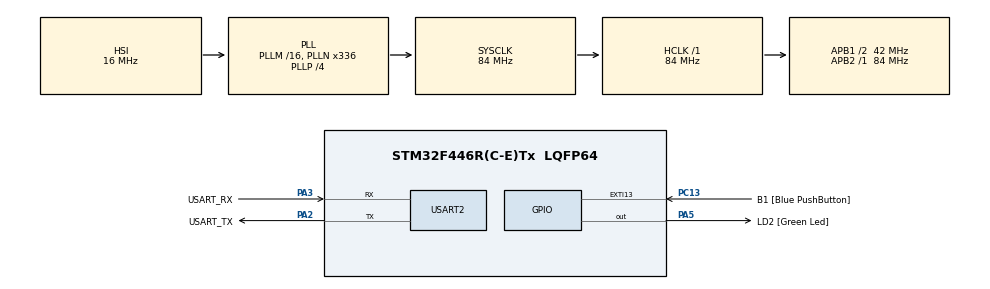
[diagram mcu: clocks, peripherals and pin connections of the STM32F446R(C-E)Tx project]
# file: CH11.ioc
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Mcu.Family=STM32F4
Mcu.Name=STM32F446R(C-E)Tx
Mcu.Package=LQFP64
NVIC.PriorityGroup=NVIC_PRIORITYGROUP_0
PA13.GPIO_Label=TMS
PA13.Mode=Serial_Wire
PA13.Signal=SYS_JTMS-SWDIO
PA14.GPIO_Label=TCK
PA14.Mode=Serial_Wire
PA14.Signal=SYS_JTCK-SWCLK
PA2.GPIO_Label=USART_TX
PA2.Mode=Asynchronous
PA2.Signal=USART2_TX
PA3.GPIO_Label=USART_RX
PA3.Mode=Asynchronous
PA3.Signal=USART2_RX
PA5.GPIO_Label=LD2 [Green Led]
PA5.Signal=GPIO_Output
PB3.GPIO_Label=SWO
PB3.Signal=SYS_JTDO-SWO
PC13.GPIO_Label=B1 [Blue PushButton]
PC13.GPIO_ModeDefaultEXTI=GPIO_MODE_IT_FALLING
PC13.Signal=GPXTI13
PC14-OSC32_IN.Mode=LSE-External-Oscillator
PC14-OSC32_IN.Signal=RCC_OSC32_IN
PC15-OSC32_OUT.Mode=LSE-External-Oscillator
PC15-OSC32_OUT.Signal=RCC_OSC32_OUT
PH0-OSC_IN.Mode=HSE-External-Oscillator
PH0-OSC_IN.Signal=RCC_OSC_IN
PH1-OSC_OUT.Mode=HSE-External-Oscillator
PH1-OSC_OUT.Signal=RCC_OSC_OUT
ProjectManager.HeapSize=0x200
ProjectManager.StackSize=0x400
ProjectManager.TargetToolchain=STM32CubeIDE
RCC.48MHZClocksFreq_Value=84000000
RCC.AHBFreq_Value=84000000
RCC.APB1CLKDivider=RCC_HCLK_DIV2
RCC.APB1Freq_Value=42000000
RCC.APB1TimFreq_Value=84000000
RCC.APB2Freq_Value=84000000
RCC.APB2TimFreq_Value=84000000
RCC.CortexFreq_Value=84000000
RCC.FLatency-AdvancedSettings=FLASH_LATENCY_2
RCC.HCLKFreq_Value=84000000
RCC.HSE_VALUE=8000000
RCC.HSI_VALUE=16000000
RCC.PLLN=336
RCC.PLLP=RCC_PLLP_DIV4
RCC.SYSCLKFreq_VALUE=84000000
RCC.SYSCLKSource=RCC_SYSCLKSOURCE_PLLCLK
RCC.USBFreq_Value=168000000
RCC.VCOOutputFreq_Value=336000000
USART2.VirtualMode=VM_ASYNC
board=NUCLEO-F446RE

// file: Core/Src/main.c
/* USER CODE BEGIN Header */
/**
  ******************************************************************************
  * @file           : main.c
  * @brief          : Main program body
  ******************************************************************************
  * @attention
  *
  * <h2><center>&copy; Copyright (c) 2021 STMicroelectronics.
  * All rights reserved.</center></h2>
  *
  * This software component is licensed by ST under BSD 3-Clause license,
  * the "License"; You may not use this file except in compliance with the
  * License. You may obtain a copy of the License at:
  *                        opensource.org/licenses/BSD-3-Clause
  *
  ******************************************************************************
  */
/* USER CODE END Header */
// 学习：引入本工程板级引脚别名和错误处理声明。
#include "main.h"

// 学习：保存外设运行状态、配置和回调关联，初始化后供后续 HAL 操作复用。
UART_HandleTypeDef huart2;

// 学习：建立本章 PLL 与总线分频；频率必须以本函数参数推导，不能跨章节照搬（此处为声明）。
void SystemClock_Config(void);
// 学习：使能端口时钟并配置板载按键/LED；复用引脚由对应外设初始化接管（此处为声明）。
static void MX_GPIO_Init(void);
// 学习：设置 USART2 为 115200、8N1，用于 ST-LINK 虚拟串口观察（此处为声明）。
static void MX_USART2_UART_Init(void);

// 学习：本子例入口：先建立 HAL/时钟/外设，再进入本文件给定的业务流程。
int main(void)
{

  /* MCU Configuration--------------------------------------------------------*/

  /* Reset of all peripherals, Initializes the Flash interface and the Systick. */
  // 学习：复位 HAL 状态、初始化 Flash 与毫秒时基，并进入 HAL_MspInit 板级回调。
  HAL_Init();

  /* Configure the system clock */
  // 学习：建立本章 PLL 与总线分频；频率必须以本函数参数推导，不能跨章节照搬。
  SystemClock_Config();

  /* Initialize all configured peripherals */
  // 学习：使能端口时钟并配置板载按键/LED；复用引脚由对应外设初始化接管。
  MX_GPIO_Init();
  // 学习：设置 USART2 为 115200、8N1，用于 ST-LINK 虚拟串口观察。
  MX_USART2_UART_Init();

  /* Infinite loop */
  /* USER CODE BEGIN WHILE */
  // 学习：进入持续业务或空转等待；是否更新输出取决于循环体。
  while (1)
  {
    /* USER CODE END WHILE */

  }
}

// 学习：建立本章 PLL 与总线分频；频率必须以本函数参数推导，不能跨章节照搬。
void SystemClock_Config(void)
{
  // 学习：为本次硬件初始化准备配置结构，随后逐字段设置有效参数。
  RCC_OscInitTypeDef RCC_OscInitStruct = {0};
  // 学习：为本次硬件初始化准备配置结构，随后逐字段设置有效参数。
  RCC_ClkInitTypeDef RCC_ClkInitStruct = {0};

  /** Configure the main internal regulator output voltage
  */
  // 学习：开启 PWR 外设或端口时钟，使寄存器访问与外设初始化具备时钟前提。
  __HAL_RCC_PWR_CLK_ENABLE();
  // 学习：设置内部调压器电压等级以满足当前系统时钟要求。
  __HAL_PWR_VOLTAGESCALING_CONFIG(PWR_REGULATOR_VOLTAGE_SCALE3);
  /** Initializes the RCC Oscillators according to the specified parameters
  * in the RCC_OscInitTypeDef structure.
  */
  // 学习：选择本次配置涉及的振荡源集合。
  RCC_OscInitStruct.OscillatorType = RCC_OSCILLATORTYPE_HSI;
  // 学习：请求内部高速 RC 状态。
  RCC_OscInitStruct.HSIState = RCC_HSI_ON;
  // 学习：设置 HSI 校准修调码。
  RCC_OscInitStruct.HSICalibrationValue = RCC_HSICALIBRATION_DEFAULT;
  // 学习：选择 PLL 状态。
  RCC_OscInitStruct.PLL.PLLState = RCC_PLL_ON;
  // 学习：选择 PLL 输入振荡源。
  RCC_OscInitStruct.PLL.PLLSource = RCC_PLLSOURCE_HSI;
  // 学习：设置 PLL 输入分频系数。
  RCC_OscInitStruct.PLL.PLLM = 16;
  // 学习：设置 PLL VCO 倍频系数。
  RCC_OscInitStruct.PLL.PLLN = 336;
  // 学习：设置主系统 PLL 输出分频。
  RCC_OscInitStruct.PLL.PLLP = RCC_PLLP_DIV4;
  // 学习：设置 PLL Q 输出分频。
  RCC_OscInitStruct.PLL.PLLQ = 2;
  // 学习：设置 PLL R 输出分频。
  RCC_OscInitStruct.PLL.PLLR = 2;
  // 学习：按结构体启用 HSI/LSE/PLL，建立系统所需振荡源。
  if (HAL_RCC_OscConfig(&RCC_OscInitStruct) != HAL_OK)
  {
    // 学习：错误分支入口；原例若关闭中断并死循环，则只能调试定位或复位恢复。
    Error_Handler();
  }
  /** Initializes the CPU, AHB and APB buses clocks
  */
  // 学习：选择本次要配置的总线时钟域。
  RCC_ClkInitStruct.ClockType = RCC_CLOCKTYPE_HCLK|RCC_CLOCKTYPE_SYSCLK
                              |RCC_CLOCKTYPE_PCLK1|RCC_CLOCKTYPE_PCLK2;
  // 学习：选择系统时钟来源。
  RCC_ClkInitStruct.SYSCLKSource = RCC_SYSCLKSOURCE_PLLCLK;
  // 学习：设置 HCLK 相对 SYSCLK 的分频。
  RCC_ClkInitStruct.AHBCLKDivider = RCC_SYSCLK_DIV1;
  // 学习：设置低速 APB 总线分频；定时器可能采用倍频时钟。
  RCC_ClkInitStruct.APB1CLKDivider = RCC_HCLK_DIV2;
  // 学习：设置高速 APB 总线分频。
  RCC_ClkInitStruct.APB2CLKDivider = RCC_HCLK_DIV1;

  // 学习：选择系统时钟并设置 AHB/APB 分频及 Flash 等待周期。
  if (HAL_RCC_ClockConfig(&RCC_ClkInitStruct, FLASH_LATENCY_2) != HAL_OK)
  {
    // 学习：错误分支入口；原例若关闭中断并死循环，则只能调试定位或复位恢复。
    Error_Handler();
  }
}

// 学习：设置 USART2 为 115200、8N1，用于 ST-LINK 虚拟串口观察。
static void MX_USART2_UART_Init(void)
{

  // 学习：选择实际硬件外设或 DMA Stream，而非新建一个外设。
  huart2.Instance = USART2;
  // 学习：设置串口速率，单位 bit/s。
  huart2.Init.BaudRate = 115200;
  // 学习：设置串口每帧数据位数。
  huart2.Init.WordLength = UART_WORDLENGTH_8B;
  // 学习：设置串口停止位数。
  huart2.Init.StopBits = UART_STOPBITS_1;
  // 学习：设置串口奇偶校验方式。
  huart2.Init.Parity = UART_PARITY_NONE;
  // 学习：选择 GPIO/DMA/UART 对应的工作模式。
  huart2.Init.Mode = UART_MODE_TX_RX;
  // 学习：选择串口硬件流控方式。
  huart2.Init.HwFlowCtl = UART_HWCONTROL_NONE;
  // 学习：设置串口过采样倍数。
  huart2.Init.OverSampling = UART_OVERSAMPLING_16;
  // 学习：按句柄中的波特率和帧格式配置 USART2，并请求 MSP 配置引脚和时钟。
  if (HAL_UART_Init(&huart2) != HAL_OK)
  {
    // 学习：错误分支入口；原例若关闭中断并死循环，则只能调试定位或复位恢复。
    Error_Handler();
  }

}

// 学习：使能端口时钟并配置板载按键/LED；复用引脚由对应外设初始化接管。
static void MX_GPIO_Init(void)
{
  // 学习：为本次硬件初始化准备配置结构，随后逐字段设置有效参数。
  GPIO_InitTypeDef GPIO_InitStruct = {0};

  /* GPIO Ports Clock Enable */
  // 学习：开启 GPIOC 外设或端口时钟，使寄存器访问与外设初始化具备时钟前提。
  __HAL_RCC_GPIOC_CLK_ENABLE();
  // 学习：开启 GPIOH 外设或端口时钟，使寄存器访问与外设初始化具备时钟前提。
  __HAL_RCC_GPIOH_CLK_ENABLE();
  // 学习：开启 GPIOA 外设或端口时钟，使寄存器访问与外设初始化具备时钟前提。
  __HAL_RCC_GPIOA_CLK_ENABLE();
  // 学习：开启 GPIOB 外设或端口时钟，使寄存器访问与外设初始化具备时钟前提。
  __HAL_RCC_GPIOB_CLK_ENABLE();

  /*Configure GPIO pin Output Level */
  // 学习：将 LD2 等输出引脚设为指定初始电平。
  HAL_GPIO_WritePin(LD2_GPIO_Port, LD2_Pin, GPIO_PIN_RESET);

  /*Configure GPIO pin : B1_Pin */
  // 学习：指定本次配置的一个或多个引脚位掩码。
  GPIO_InitStruct.Pin = B1_Pin;
  // 学习：选择 GPIO/DMA/UART 对应的工作模式。
  GPIO_InitStruct.Mode = GPIO_MODE_IT_FALLING;
  // 学习：设置内部上拉/下拉/无拉电阻。
  GPIO_InitStruct.Pull = GPIO_NOPULL;
  // 学习：按 Pin/Mode/Pull/Speed/Alternate 将端口引脚配置为业务所需模式。
  HAL_GPIO_Init(B1_GPIO_Port, &GPIO_InitStruct);

  /*Configure GPIO pin : LD2_Pin */
  // 学习：指定本次配置的一个或多个引脚位掩码。
  GPIO_InitStruct.Pin = LD2_Pin;
  // 学习：选择 GPIO/DMA/UART 对应的工作模式。
  GPIO_InitStruct.Mode = GPIO_MODE_OUTPUT_PP;
  // 学习：设置内部上拉/下拉/无拉电阻。
  GPIO_InitStruct.Pull = GPIO_NOPULL;
  // 学习：设置 GPIO 输出沿驱动速度等级。
  GPIO_InitStruct.Speed = GPIO_SPEED_FREQ_LOW;
  // 学习：按 Pin/Mode/Pull/Speed/Alternate 将端口引脚配置为业务所需模式。
  HAL_GPIO_Init(LD2_GPIO_Port, &GPIO_InitStruct);

}

// 学习：错误分支入口；原例若关闭中断并死循环，则只能调试定位或复位恢复。
void Error_Handler(void)
{
  /* USER CODE BEGIN Error_Handler_Debug */
  /* User can add his own implementation to report the HAL error return state */
  // 学习：在 Error_Handler 中关闭可屏蔽中断，进入停止前进的错误状态。
  __disable_irq();
  // 学习：进入持续业务或空转等待；是否更新输出取决于循环体。
  while (1)
  {
  }
  /* USER CODE END Error_Handler_Debug */
}

// 学习：编译选择：仅启用完整参数断言时保留该回调模板。

/************************ (C) COPYRIGHT STMicroelectronics *****END OF FILE****/
